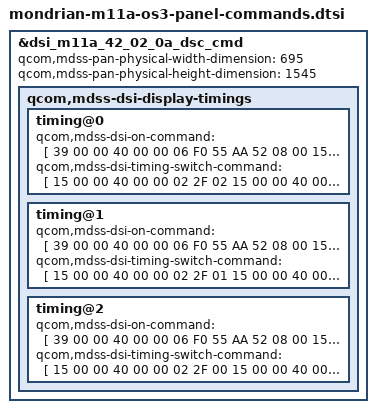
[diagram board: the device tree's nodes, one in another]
// SPDX-License-Identifier: GPL-2.0-only
/*
 * GENERATED by tools/extract_stock_m11a_commands.py - do not edit.
 *
 * M11A physical size and the initialization and refresh-rate switch commands of every mode,
 * from the stock OS3.0.8.0.VMNCNXM device tree (Cape DTB of vendor_boot
 * sha256 963e51a382461109..., mondrian entry of dtbo
 * sha256 8580bc0bbe689784...). Xiaomi's public M11A source carries an
 * older 57-packet initialization; stock uses these sequences per mode.
 */

&dsi_m11a_42_02_0a_dsc_cmd {
	/* Physical size in 0.1 mm, as stock reports it (DPI). */
	qcom,mdss-pan-physical-width-dimension = <695>;
	qcom,mdss-pan-physical-height-dimension = <1545>;

	qcom,mdss-dsi-display-timings {
		timing@0 { /* 60 Hz */
			/* 135 packets */
			qcom,mdss-dsi-on-command = [
				39 00 00 40 00 00 06 F0 55 AA 52 08 00
				15 00 00 40 00 00 02 6F 1A
				15 00 00 00 00 00 02 C2 00
				39 00 00 40 00 00 06 F0 55 AA 52 08 01
				15 00 00 40 00 00 02 6F 0E
				15 00 00 40 00 00 02 B4 1F
				39 00 00 40 00 00 05 FF AA 55 A5 80
				15 00 00 40 00 00 02 6F 02
				15 00 00 00 00 00 02 F5 10
				39 00 00 40 00 00 06 F0 55 AA 52 08 01
				39 00 00 00 00 00 03 B1 06 06
				39 00 00 40 00 00 06 F0 55 AA 52 08 01
				15 00 00 40 00 00 02 6F 01
				15 00 00 40 00 00 02 C4 E3
				39 00 00 40 00 00 05 FF AA 55 A5 80
				15 00 00 40 00 00 02 6F 18
				15 00 00 00 00 00 02 F8 19
				39 00 00 40 00 00 06 F0 55 AA 52 08 01
				15 00 00 40 00 00 02 6F 01
				39 00 00 00 00 00 04 C5 0B 0B 0B
				39 00 00 40 00 00 06 F0 55 AA 52 08 04
				15 00 00 00 00 00 02 C0 20
				39 00 00 40 00 00 06 F0 55 AA 52 08 00
				15 00 00 40 00 00 02 6F 20
				39 00 00 40 00 00 09 C6 55 55 55 55 55 55 55 55
				39 00 00 40 00 00 05 FF AA 55 A5 80
				15 00 00 40 00 00 02 6F 1B
				15 00 00 40 00 00 02 F4 55
				15 00 00 40 00 00 02 6F 19
				15 00 00 00 00 00 02 F2 00
				39 00 00 40 00 00 05 FF AA 55 A5 81
				15 00 00 40 00 00 02 6F 18
				15 00 00 00 00 00 02 FB 04
				39 00 00 40 00 00 05 FF AA 55 A5 81
				15 00 00 40 00 00 02 6F 07
				15 00 00 00 00 00 02 FC 08
				39 00 00 40 00 00 05 2A 00 00 05 9F
				39 00 00 00 00 00 05 2B 00 00 0C 7F
				15 00 00 40 00 00 02 90 03
				39 00 00 00 00 00 13 91 AB A8 00 20 D2 00 02 86 03 5E 00 0A 03 5B 02 63 10 F0
				15 00 00 40 00 00 02 35 00
				15 00 00 00 00 00 02 5A 01
				39 00 00 40 00 00 06 F0 55 AA 52 08 01
				39 00 00 40 00 00 06 D2 00 00 00 00 15
				15 00 00 40 00 00 02 6F 05
				39 00 00 40 00 00 04 D2 01 00 00
				15 00 00 40 00 00 02 6F 0E
				39 00 00 40 00 00 06 D2 00 00 10 13 32
				39 00 00 40 00 00 0B E4 80 03 00 00 00 00 00 00 00 33
				15 00 00 40 00 00 02 6F 0A
				39 00 00 00 00 00 07 E4 80 03 00 10 00 53
				39 00 00 40 00 00 05 3B 00 18 00 10
				15 00 00 40 00 00 02 53 20
				39 00 00 40 00 00 07 51 00 00 0F FF 0F FF
				15 00 00 40 00 00 02 9C 01
				15 00 00 00 00 00 02 2C 00
				15 00 00 40 00 00 02 2F 02
				15 00 00 40 00 00 02 5F 01
				15 00 00 40 00 00 02 26 00
				15 00 00 40 00 00 02 8B 00
				39 00 00 40 00 00 06 F0 55 AA 52 08 00
				15 00 00 40 00 00 02 6F 03
				15 00 00 40 00 00 02 C0 10
				15 00 00 40 00 00 02 6F 31
				15 00 00 40 00 00 02 DF 21
				39 00 00 40 00 00 06 F0 55 AA 52 08 02
				15 00 00 40 00 00 02 CC 30
				15 00 00 40 14 00 02 CE 01
				15 00 00 00 00 00 02 CC 00
				39 00 00 40 00 00 06 F0 55 AA 52 08 01
				39 00 00 40 00 00 0C C3 90 04 20 13 FF 00 04 20 0E FF 00
				15 00 00 40 00 00 02 6F 0B
				39 00 00 40 00 00 07 C3 06 30 1D 06 67 14
				15 00 00 40 00 00 02 6F 11
				39 00 00 40 00 00 07 C3 06 30 1D 06 67 14
				15 00 00 40 00 00 02 6F 17
				39 00 00 40 00 00 07 C3 06 30 1D 06 67 14
				15 00 00 40 00 00 02 6F 1D
				39 00 00 40 00 00 07 C3 06 30 1D 06 67 14
				15 00 00 40 00 00 02 6F 23
				39 00 00 00 00 00 07 C3 06 30 1D 06 67 14
				39 00 00 40 00 00 06 F0 55 AA 52 08 00
				15 00 00 40 00 00 02 6F 01
				15 00 00 00 00 00 02 BE 45
				15 00 00 40 00 00 02 6F 05
				15 00 00 00 00 00 02 BE 88
				39 00 00 40 00 00 06 F0 55 AA 52 08 00
				15 00 00 40 00 00 02 6F 07
				39 00 00 40 00 00 05 B5 2A 1E 00 32
				39 00 00 40 00 00 1A B7 40 40 41 42 43 44 45 46 47 48 49 4A 4B 4C 4D 4E 4F 50 51 51 51 51 51 51 51
				15 00 00 40 00 00 02 6F 19
				39 00 00 40 00 00 0D B7 17 88 99 AA BB CC DD EE FF FF FF FF
				15 00 00 40 00 00 02 6F 25
				39 00 00 00 00 00 19 B7 BA FF 77 EF 67 DF 57 CF 47 BF 37 AF 27 9F 17 8F 07 7F FF FF FF FF FF FF
				39 00 00 40 00 00 06 F0 55 AA 52 08 07
				15 00 00 00 00 00 02 C0 B1
				39 00 00 40 00 00 06 F0 55 AA 52 08 00
				15 00 00 40 00 00 02 6F 18
				39 00 00 40 00 00 17 B4 00 10 00 10 00 10 00 10 00 10 00 10 00 10 00 10 00 10 00 10 00 10
				15 00 00 40 00 00 02 6F 46
				39 00 00 40 00 00 17 B4 00 10 00 10 00 10 00 10 00 10 00 10 00 10 00 10 00 10 00 10 00 10
				15 00 00 40 00 00 02 6F 74
				39 00 00 00 00 00 17 B4 00 10 00 10 00 10 00 10 00 10 00 10 00 10 00 10 00 10 00 10 00 10
				05 00 00 00 78 00 02 11 00
				05 00 00 00 00 00 02 29 00
				39 00 00 40 00 00 06 F0 55 AA 52 08 04
				15 00 00 40 00 00 02 6F 16
				15 00 00 40 00 00 02 D2 19
				15 00 00 40 00 00 02 6F 16
				15 00 00 40 00 00 02 D4 18
				15 00 00 40 00 00 02 6F 2F
				15 00 00 40 00 00 02 D2 28
				15 00 00 40 00 00 02 6F 2F
				15 00 00 40 00 00 02 D4 27
				15 00 00 40 00 00 02 6F 48
				15 00 00 40 00 00 02 D2 18
				15 00 00 40 00 00 02 6F 48
				15 00 00 00 00 00 02 D4 17
				39 00 00 40 00 00 06 F0 55 AA 52 08 02
				15 00 00 40 00 00 02 BF 0A
				39 00 00 40 00 00 03 B0 00 C8
				39 00 00 40 00 00 03 B3 00 C8
				39 00 00 40 00 00 03 B6 00 C8
				15 00 00 40 00 00 02 BF 1A
				39 00 00 40 00 00 03 B0 00 C8
				39 00 00 40 00 00 03 B3 00 C8
				39 00 00 40 00 00 03 B6 00 C8
				15 00 00 40 00 00 02 BF 2A
				39 00 00 40 00 00 03 B0 00 C8
				39 00 00 40 00 00 03 B3 00 C8
				39 00 00 40 00 00 03 B6 00 C8
				15 00 00 40 00 00 02 BF 3A
				39 00 00 40 00 00 03 B0 00 C8
				39 00 00 40 00 00 03 B3 00 C8
				39 00 00 00 00 00 03 B6 00 C8
			];
			/* 10 packets */
			qcom,mdss-dsi-timing-switch-command = [
				15 00 00 40 00 00 02 2F 02
				15 00 00 40 00 00 02 8B 00
				39 00 00 40 00 00 06 F0 55 AA 52 08 00
				15 00 00 40 00 00 02 6F 03
				15 00 00 40 00 00 02 C0 10
				15 00 00 40 00 00 02 6F 31
				15 00 00 40 00 00 02 DF 21
				39 00 00 40 00 00 06 F0 55 AA 52 08 02
				15 00 00 40 00 00 02 CC 30
				15 00 00 00 00 00 02 CE 01
			];
		};

		timing@1 { /* 90 Hz */
			/* 135 packets */
			qcom,mdss-dsi-on-command = [
				39 00 00 40 00 00 06 F0 55 AA 52 08 00
				15 00 00 40 00 00 02 6F 1A
				15 00 00 00 00 00 02 C2 00
				39 00 00 40 00 00 06 F0 55 AA 52 08 01
				15 00 00 40 00 00 02 6F 0E
				15 00 00 40 00 00 02 B4 1F
				39 00 00 40 00 00 05 FF AA 55 A5 80
				15 00 00 40 00 00 02 6F 02
				15 00 00 00 00 00 02 F5 10
				39 00 00 40 00 00 06 F0 55 AA 52 08 01
				39 00 00 00 00 00 03 B1 06 06
				39 00 00 40 00 00 06 F0 55 AA 52 08 01
				15 00 00 40 00 00 02 6F 01
				15 00 00 40 00 00 02 C4 E3
				39 00 00 40 00 00 05 FF AA 55 A5 80
				15 00 00 40 00 00 02 6F 18
				15 00 00 00 00 00 02 F8 19
				39 00 00 40 00 00 06 F0 55 AA 52 08 01
				15 00 00 40 00 00 02 6F 01
				39 00 00 40 00 00 04 C5 0B 0B 0B
				39 00 00 40 00 00 06 F0 55 AA 52 08 04
				15 00 00 00 00 00 02 C0 20
				39 00 00 40 00 00 06 F0 55 AA 52 08 00
				15 00 00 40 00 00 02 6F 20
				39 00 00 40 00 00 09 C6 55 55 55 55 55 55 55 55
				39 00 00 40 00 00 05 FF AA 55 A5 80
				15 00 00 40 00 00 02 6F 1B
				15 00 00 00 00 00 02 F4 55
				15 00 00 40 00 00 02 6F 19
				15 00 00 00 00 00 02 F2 00
				39 00 00 40 00 00 05 FF AA 55 A5 81
				15 00 00 40 00 00 02 6F 18
				15 00 00 00 00 00 02 FB 04
				39 00 00 40 00 00 05 FF AA 55 A5 81
				15 00 00 40 00 00 02 6F 07
				15 00 00 00 00 00 02 FC 08
				39 00 00 40 00 00 05 2A 00 00 05 9F
				39 00 00 00 00 00 05 2B 00 00 0C 7F
				15 00 00 40 00 00 02 90 03
				39 00 00 00 00 00 13 91 AB A8 00 20 D2 00 02 86 03 5E 00 0A 03 5B 02 63 10 F0
				15 00 00 40 00 00 02 35 00
				15 00 00 00 00 00 02 5A 01
				39 00 00 40 00 00 06 F0 55 AA 52 08 01
				39 00 00 40 00 00 06 D2 00 00 00 00 15
				15 00 00 40 00 00 02 6F 05
				39 00 00 40 00 00 04 D2 01 00 00
				15 00 00 40 00 00 02 6F 0E
				39 00 00 40 00 00 06 D2 00 00 10 13 32
				39 00 00 40 00 00 0B E4 80 03 00 00 00 00 00 00 00 33
				15 00 00 40 00 00 02 6F 0A
				39 00 00 00 00 00 07 E4 80 03 00 10 00 53
				39 00 00 00 00 00 05 3B 00 18 00 10
				15 00 00 40 00 00 02 53 20
				39 00 00 40 00 00 07 51 00 00 0F FF 0F FF
				15 00 00 40 00 00 02 9C 01
				15 00 00 00 00 00 02 2C 00
				15 00 00 40 00 00 02 2F 01
				15 00 00 40 00 00 02 5F 01
				15 00 00 40 00 00 02 26 00
				15 00 00 40 00 00 02 8B 10
				39 00 00 40 00 00 06 F0 55 AA 52 08 00
				15 00 00 40 00 00 02 6F 03
				15 00 00 40 00 00 02 C0 10
				15 00 00 40 00 00 02 6F 31
				15 00 00 40 00 00 02 DF 20
				39 00 00 40 00 00 06 F0 55 AA 52 08 02
				15 00 00 40 00 00 02 CC 30
				15 00 00 40 14 00 02 CE 01
				15 00 00 00 00 00 02 CC 00
				39 00 00 40 00 00 06 F0 55 AA 52 08 01
				39 00 00 40 00 00 0C C3 90 04 20 13 FF 00 04 20 0E FF 00
				15 00 00 40 00 00 02 6F 0B
				39 00 00 40 00 00 07 C3 06 30 1D 06 67 14
				15 00 00 40 00 00 02 6F 11
				39 00 00 40 00 00 07 C3 06 30 1D 06 67 14
				15 00 00 40 00 00 02 6F 17
				39 00 00 40 00 00 07 C3 06 30 1D 06 67 14
				15 00 00 40 00 00 02 6F 1D
				39 00 00 40 00 00 07 C3 06 30 1D 06 67 14
				15 00 00 40 00 00 02 6F 23
				39 00 00 00 00 00 07 C3 06 30 1D 06 67 14
				39 00 00 40 00 00 06 F0 55 AA 52 08 00
				15 00 00 40 00 00 02 6F 01
				15 00 00 00 00 00 02 BE 45
				15 00 00 40 00 00 02 6F 05
				15 00 00 00 00 00 02 BE 88
				39 00 00 40 00 00 06 F0 55 AA 52 08 00
				15 00 00 40 00 00 02 6F 07
				39 00 00 40 00 00 05 B5 2A 1E 00 32
				39 00 00 40 00 00 1A B7 40 40 41 42 43 44 45 46 47 48 49 4A 4B 4C 4D 4E 4F 50 51 51 51 51 51 51 51
				15 00 00 40 00 00 02 6F 19
				39 00 00 40 00 00 0D B7 17 88 99 AA BB CC DD EE FF FF FF FF
				15 00 00 40 00 00 02 6F 25
				39 00 00 00 00 00 19 B7 BA FF 77 EF 67 DF 57 CF 47 BF 37 AF 27 9F 17 8F 07 7F FF FF FF FF FF FF
				39 00 00 40 00 00 06 F0 55 AA 52 08 07
				15 00 00 00 00 00 02 C0 B1
				39 00 00 40 00 00 06 F0 55 AA 52 08 00
				15 00 00 40 00 00 02 6F 18
				39 00 00 40 00 00 17 B4 00 10 00 10 00 10 00 10 00 10 00 10 00 10 00 10 00 10 00 10 00 10
				15 00 00 40 00 00 02 6F 46
				39 00 00 40 00 00 17 B4 00 10 00 10 00 10 00 10 00 10 00 10 00 10 00 10 00 10 00 10 00 10
				15 00 00 40 00 00 02 6F 74
				39 00 00 00 00 00 17 B4 00 10 00 10 00 10 00 10 00 10 00 10 00 10 00 10 00 10 00 10 00 10
				05 00 00 00 78 00 02 11 00
				05 00 00 00 00 00 02 29 00
				39 00 00 40 00 00 06 F0 55 AA 52 08 04
				15 00 00 40 00 00 02 6F 16
				15 00 00 40 00 00 02 D2 19
				15 00 00 40 00 00 02 6F 16
				15 00 00 40 00 00 02 D4 18
				15 00 00 40 00 00 02 6F 2F
				15 00 00 40 00 00 02 D2 28
				15 00 00 40 00 00 02 6F 2F
				15 00 00 40 00 00 02 D4 27
				15 00 00 40 00 00 02 6F 48
				15 00 00 40 00 00 02 D2 18
				15 00 00 40 00 00 02 6F 48
				15 00 00 00 00 00 02 D4 17
				39 00 00 40 00 00 06 F0 55 AA 52 08 02
				15 00 00 40 00 00 02 BF 0A
				39 00 00 40 00 00 03 B0 00 C8
				39 00 00 40 00 00 03 B3 00 C8
				39 00 00 40 00 00 03 B6 00 C8
				15 00 00 40 00 00 02 BF 1A
				39 00 00 40 00 00 03 B0 00 C8
				39 00 00 40 00 00 03 B3 00 C8
				39 00 00 40 00 00 03 B6 00 C8
				15 00 00 40 00 00 02 BF 2A
				39 00 00 40 00 00 03 B0 00 C8
				39 00 00 40 00 00 03 B3 00 C8
				39 00 00 40 00 00 03 B6 00 C8
				15 00 00 40 00 00 02 BF 3A
				39 00 00 40 00 00 03 B0 00 C8
				39 00 00 40 00 00 03 B3 00 C8
				39 00 00 00 00 00 03 B6 00 C8
			];
			/* 10 packets */
			qcom,mdss-dsi-timing-switch-command = [
				15 00 00 40 00 00 02 2F 01
				15 00 00 40 00 00 02 8B 10
				39 00 00 40 00 00 06 F0 55 AA 52 08 00
				15 00 00 40 00 00 02 6F 03
				15 00 00 40 00 00 02 C0 10
				15 00 00 40 00 00 02 6F 31
				15 00 00 40 00 00 02 DF 20
				39 00 00 40 00 00 06 F0 55 AA 52 08 02
				15 00 00 40 00 00 02 CC 30
				15 00 00 00 00 00 02 CE 01
			];
		};

		timing@2 { /* 120 Hz */
			/* 135 packets */
			qcom,mdss-dsi-on-command = [
				39 00 00 40 00 00 06 F0 55 AA 52 08 00
				15 00 00 40 00 00 02 6F 1A
				15 00 00 00 00 00 02 C2 00
				39 00 00 40 00 00 06 F0 55 AA 52 08 01
				15 00 00 40 00 00 02 6F 0E
				15 00 00 40 00 00 02 B4 1F
				39 00 00 40 00 00 05 FF AA 55 A5 80
				15 00 00 40 00 00 02 6F 02
				15 00 00 00 00 00 02 F5 10
				39 00 00 40 00 00 06 F0 55 AA 52 08 01
				39 00 00 00 00 00 03 B1 06 06
				39 00 00 40 00 00 06 F0 55 AA 52 08 01
				15 00 00 40 00 00 02 6F 01
				15 00 00 40 00 00 02 C4 E3
				39 00 00 40 00 00 05 FF AA 55 A5 80
				15 00 00 40 00 00 02 6F 18
				15 00 00 00 00 00 02 F8 19
				39 00 00 40 00 00 06 F0 55 AA 52 08 01
				15 00 00 40 00 00 02 6F 01
				39 00 00 00 00 00 04 C5 0B 0B 0B
				39 00 00 40 00 00 06 F0 55 AA 52 08 04
				15 00 00 00 00 00 02 C0 20
				39 00 00 40 00 00 06 F0 55 AA 52 08 00
				15 00 00 40 00 00 02 6F 20
				39 00 00 40 00 00 09 C6 55 55 55 55 55 55 55 55
				39 00 00 40 00 00 05 FF AA 55 A5 80
				15 00 00 40 00 00 02 6F 1B
				15 00 00 00 00 00 02 F4 55
				15 00 00 40 00 00 02 6F 19
				15 00 00 00 00 00 02 F2 00
				39 00 00 40 00 00 05 FF AA 55 A5 81
				15 00 00 40 00 00 02 6F 18
				15 00 00 00 00 00 02 FB 04
				39 00 00 40 00 00 05 FF AA 55 A5 81
				15 00 00 40 00 00 02 6F 07
				15 00 00 00 00 00 02 FC 08
				39 00 00 40 00 00 05 2A 00 00 05 9F
				39 00 00 00 00 00 05 2B 00 00 0C 7F
				15 00 00 40 00 00 02 90 03
				39 00 00 00 00 00 13 91 AB A8 00 20 D2 00 02 86 03 5E 00 0A 03 5B 02 63 10 F0
				15 00 00 40 00 00 02 35 00
				15 00 00 00 00 00 02 5A 01
				39 00 00 40 00 00 06 F0 55 AA 52 08 01
				39 00 00 40 00 00 06 D2 00 00 00 00 15
				15 00 00 40 00 00 02 6F 05
				39 00 00 40 00 00 04 D2 01 00 00
				15 00 00 40 00 00 02 6F 0E
				39 00 00 40 00 00 06 D2 00 00 10 13 32
				39 00 00 40 00 00 0B E4 80 03 00 00 00 00 00 00 00 33
				15 00 00 40 00 00 02 6F 0A
				39 00 00 00 00 00 07 E4 80 03 00 10 00 53
				39 00 00 00 00 00 05 3B 00 18 00 10
				15 00 00 40 00 00 02 53 20
				39 00 00 40 00 00 07 51 00 00 0F FF 0F FF
				15 00 00 40 00 00 02 9C 01
				15 00 00 00 00 00 02 2C 00
				15 00 00 40 00 00 02 2F 00
				15 00 00 40 00 00 02 5F 01
				15 00 00 40 00 00 02 26 00
				15 00 00 40 00 00 02 8B 00
				39 00 00 40 00 00 06 F0 55 AA 52 08 00
				15 00 00 40 00 00 02 6F 03
				15 00 00 40 00 00 02 C0 10
				15 00 00 40 00 00 02 6F 31
				15 00 00 40 00 00 02 DF 20
				39 00 00 40 00 00 06 F0 55 AA 52 08 02
				15 00 00 40 00 00 02 CC 30
				15 00 00 40 14 00 02 CE 01
				15 00 00 00 00 00 02 CC 00
				39 00 00 40 00 00 06 F0 55 AA 52 08 01
				39 00 00 40 00 00 0C C3 90 04 20 13 FF 00 04 20 0E FF 00
				15 00 00 40 00 00 02 6F 0B
				39 00 00 40 00 00 07 C3 06 30 1D 06 67 14
				15 00 00 40 00 00 02 6F 11
				39 00 00 40 00 00 07 C3 06 30 1D 06 67 14
				15 00 00 40 00 00 02 6F 17
				39 00 00 40 00 00 07 C3 06 30 1D 06 67 14
				15 00 00 40 00 00 02 6F 1D
				39 00 00 40 00 00 07 C3 06 30 1D 06 67 14
				15 00 00 40 00 00 02 6F 23
				39 00 00 00 00 00 07 C3 06 30 1D 06 67 14
				39 00 00 40 00 00 06 F0 55 AA 52 08 00
				15 00 00 40 00 00 02 6F 01
				15 00 00 00 00 00 02 BE 45
				15 00 00 40 00 00 02 6F 05
				15 00 00 00 00 00 02 BE 88
				39 00 00 40 00 00 06 F0 55 AA 52 08 00
				15 00 00 40 00 00 02 6F 07
				39 00 00 40 00 00 05 B5 2A 1E 00 32
				39 00 00 40 00 00 1A B7 40 40 41 42 43 44 45 46 47 48 49 4A 4B 4C 4D 4E 4F 50 51 51 51 51 51 51 51
				15 00 00 40 00 00 02 6F 19
				39 00 00 40 00 00 0D B7 17 88 99 AA BB CC DD EE FF FF FF FF
				15 00 00 40 00 00 02 6F 25
				39 00 00 00 00 00 19 B7 BA FF 77 EF 67 DF 57 CF 47 BF 37 AF 27 9F 17 8F 07 7F FF FF FF FF FF FF
				39 00 00 40 00 00 06 F0 55 AA 52 08 07
				15 00 00 00 00 00 02 C0 B1
				39 00 00 40 00 00 06 F0 55 AA 52 08 00
				15 00 00 40 00 00 02 6F 18
				39 00 00 40 00 00 17 B4 00 10 00 10 00 10 00 10 00 10 00 10 00 10 00 10 00 10 00 10 00 10
				15 00 00 40 00 00 02 6F 46
				39 00 00 40 00 00 17 B4 00 10 00 10 00 10 00 10 00 10 00 10 00 10 00 10 00 10 00 10 00 10
				15 00 00 40 00 00 02 6F 74
				39 00 00 00 00 00 17 B4 00 10 00 10 00 10 00 10 00 10 00 10 00 10 00 10 00 10 00 10 00 10
				05 00 00 00 78 00 02 11 00
				05 00 00 00 00 00 02 29 00
				39 00 00 40 00 00 06 F0 55 AA 52 08 04
				15 00 00 40 00 00 02 6F 16
				15 00 00 40 00 00 02 D2 19
				15 00 00 40 00 00 02 6F 16
				15 00 00 40 00 00 02 D4 18
				15 00 00 40 00 00 02 6F 2F
				15 00 00 40 00 00 02 D2 28
				15 00 00 40 00 00 02 6F 2F
				15 00 00 40 00 00 02 D4 27
				15 00 00 40 00 00 02 6F 48
				15 00 00 40 00 00 02 D2 18
				15 00 00 40 00 00 02 6F 48
				15 00 00 00 00 00 02 D4 17
				39 00 00 40 00 00 06 F0 55 AA 52 08 02
				15 00 00 40 00 00 02 BF 0A
				39 00 00 40 00 00 03 B0 00 C8
				39 00 00 40 00 00 03 B3 00 C8
				39 00 00 40 00 00 03 B6 00 C8
				15 00 00 40 00 00 02 BF 1A
				39 00 00 40 00 00 03 B0 00 C8
				39 00 00 40 00 00 03 B3 00 C8
				39 00 00 40 00 00 03 B6 00 C8
				15 00 00 40 00 00 02 BF 2A
				39 00 00 40 00 00 03 B0 00 C8
				39 00 00 40 00 00 03 B3 00 C8
				39 00 00 40 00 00 03 B6 00 C8
				15 00 00 40 00 00 02 BF 3A
				39 00 00 40 00 00 03 B0 00 C8
				39 00 00 40 00 00 03 B3 00 C8
				39 00 00 00 00 00 03 B6 00 C8
			];
			/* 10 packets */
			qcom,mdss-dsi-timing-switch-command = [
				15 00 00 40 00 00 02 2F 00
				15 00 00 40 00 00 02 8B 00
				39 00 00 40 00 00 06 F0 55 AA 52 08 00
				15 00 00 40 00 00 02 6F 03
				15 00 00 40 00 00 02 C0 10
				15 00 00 40 00 00 02 6F 31
				15 00 00 40 00 00 02 DF 20
				39 00 00 40 00 00 06 F0 55 AA 52 08 02
				15 00 00 40 00 00 02 CC 30
				15 00 00 00 00 00 02 CE 01
			];
		};
	};
};
